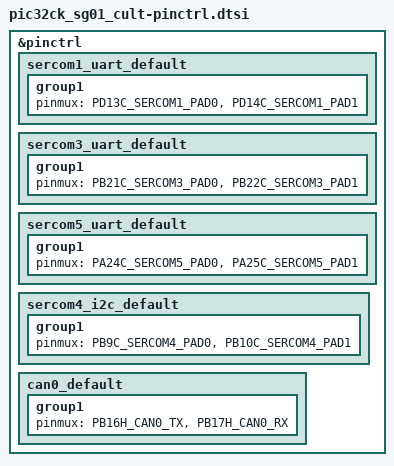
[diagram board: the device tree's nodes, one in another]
/*
 * SPDX-FileCopyrightText: Copyright (c) 2026 Microchip Technology Inc.
 *
 * SPDX-License-Identifier: Apache-2.0
 */

#include <dt-bindings/pic32c/pic32ck_sg_gc/pic32ck_sg01/pic32ck2051sg01144-pinctrl.h>

&pinctrl {
	sercom1_uart_default: sercom1_uart_default {
		group1 {
			pinmux = <PD13C_SERCOM1_PAD0>, /* TX */
				 <PD14C_SERCOM1_PAD1>; /* RX */
		};
	};

	sercom3_uart_default: sercom3_uart_default {
		group1 {
			pinmux = <PB21C_SERCOM3_PAD0>, /* TX */
				 <PB22C_SERCOM3_PAD1>; /* RX */
		};
	};

	sercom5_uart_default: sercom5_uart_default {
		group1 {
			pinmux = <PA24C_SERCOM5_PAD0>, /* TX */
				 <PA25C_SERCOM5_PAD1>; /* RX */
		};
	};

	sercom4_i2c_default: sercom4_i2c_default {
		group1 {
			pinmux = <PB9C_SERCOM4_PAD0>,  /* SDA */
				 <PB10C_SERCOM4_PAD1>; /* SCL */
		};
	};

	/* CAN0 pinctrl - PB16=TX, PB17=RX per user guide */
	can0_default: can0_default {
		group1 {
			pinmux = <PB16H_CAN0_TX>,
				 <PB17H_CAN0_RX>;
		};
	};
};
